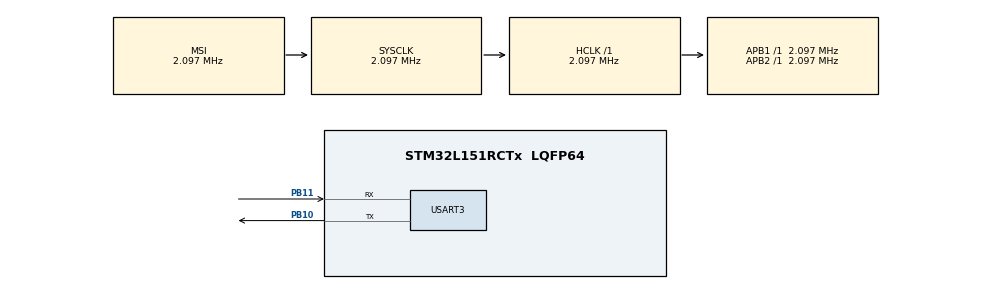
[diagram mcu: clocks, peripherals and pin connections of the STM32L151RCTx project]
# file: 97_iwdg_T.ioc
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IWDG.Prescaler=IWDG_PRESCALER_64
IWDG.Reload=500
Mcu.Family=STM32L1
Mcu.Name=STM32L151RCTx
Mcu.Package=LQFP64
NVIC.PriorityGroup=NVIC_PRIORITYGROUP_4
PB10.Mode=Asynchronous
PB10.Signal=USART3_TX
PB11.Mode=Asynchronous
PB11.Signal=USART3_RX
ProjectManager.HeapSize=0x200
ProjectManager.StackSize=0x400
ProjectManager.TargetToolchain=MDK-ARM V5.32
RCC.AHBFreq_Value=2097000
RCC.APB1Freq_Value=2097000
RCC.APB2Freq_Value=2097000
RCC.HSE_VALUE=24000000
RCC.HSI_VALUE=16000000
RCC.LSE_VALUE=32768
RCC.MSI_VALUE=2097000
RCC.SYSCLKFreq_VALUE=2097000
RCC.VCOOutputFreq_Value=48000000
USART3.VirtualMode=VM_ASYNC
VP_IWDG_VS_IWDG.Mode=IWDG_Activate
board=custom

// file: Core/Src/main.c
/* USER CODE BEGIN Header */
/**
  ******************************************************************************
  * @file           : main.c
  * @brief          : Main program body
  ******************************************************************************
  * @attention
  *
  * Copyright (c) 2024 STMicroelectronics.
  * All rights reserved.
  *
  * This software is licensed under terms that can be found in the LICENSE file
  * in the root directory of this software component.
  * If no LICENSE file comes with this software, it is provided AS-IS.
  *
  ******************************************************************************
  */
/* USER CODE END Header */
#include "main.h"

/* USER CODE BEGIN Includes */
#include "stdio.h"
/* USER CODE END Includes */

IWDG_HandleTypeDef hiwdg;

UART_HandleTypeDef huart3;

void SystemClock_Config(void);
static void MX_GPIO_Init(void);
static void MX_IWDG_Init(void);
static void MX_USART3_UART_Init(void);

int main(void)
{

  /* MCU Configuration--------------------------------------------------------*/

  /* Reset of all peripherals, Initializes the Flash interface and the Systick. */
  HAL_Init();

  /* Configure the system clock */
  SystemClock_Config();

  /* Initialize all configured peripherals */
  MX_GPIO_Init();
  MX_IWDG_Init();
  MX_USART3_UART_Init();
  /* USER CODE BEGIN 2 */
	char message[] = "message\r\n";
	sprintf(message, "reset\r\n");
	HAL_UART_Transmit(&huart3, (uint8_t *) message, sizeof(message) - 1, HAL_MAX_DELAY);
  /* USER CODE END 2 */

  /* Infinite loop */
  /* USER CODE BEGIN WHILE */
  while (1)
  {
  		HAL_Delay(100);
		sprintf(message, "feed\r\n");
		HAL_UART_Transmit(&huart3, (uint8_t *) message, sizeof(message) - 1, HAL_MAX_DELAY);
		// HAL_IWDG_Refresh(&hiwdg);  //ι��
    /* USER CODE END WHILE */

  }
}

void SystemClock_Config(void)
{
  RCC_OscInitTypeDef RCC_OscInitStruct = {0};
  RCC_ClkInitTypeDef RCC_ClkInitStruct = {0};

  /** Configure the main internal regulator output voltage
  */
  __HAL_PWR_VOLTAGESCALING_CONFIG(PWR_REGULATOR_VOLTAGE_SCALE1);

  /** Initializes the RCC Oscillators according to the specified parameters
  * in the RCC_OscInitTypeDef structure.
  */
  RCC_OscInitStruct.OscillatorType = RCC_OSCILLATORTYPE_LSI|RCC_OSCILLATORTYPE_MSI;
  RCC_OscInitStruct.LSIState = RCC_LSI_ON;
  RCC_OscInitStruct.MSIState = RCC_MSI_ON;
  RCC_OscInitStruct.MSICalibrationValue = 0;
  RCC_OscInitStruct.MSIClockRange = RCC_MSIRANGE_5;
  RCC_OscInitStruct.PLL.PLLState = RCC_PLL_NONE;
  if (HAL_RCC_OscConfig(&RCC_OscInitStruct) != HAL_OK)
  {
    Error_Handler();
  }

  /** Initializes the CPU, AHB and APB buses clocks
  */
  RCC_ClkInitStruct.ClockType = RCC_CLOCKTYPE_HCLK|RCC_CLOCKTYPE_SYSCLK
                              |RCC_CLOCKTYPE_PCLK1|RCC_CLOCKTYPE_PCLK2;
  RCC_ClkInitStruct.SYSCLKSource = RCC_SYSCLKSOURCE_MSI;
  RCC_ClkInitStruct.AHBCLKDivider = RCC_SYSCLK_DIV1;
  RCC_ClkInitStruct.APB1CLKDivider = RCC_HCLK_DIV1;
  RCC_ClkInitStruct.APB2CLKDivider = RCC_HCLK_DIV1;

  if (HAL_RCC_ClockConfig(&RCC_ClkInitStruct, FLASH_LATENCY_0) != HAL_OK)
  {
    Error_Handler();
  }
}

static void MX_IWDG_Init(void)
{

  hiwdg.Instance = IWDG;
  hiwdg.Init.Prescaler = IWDG_PRESCALER_64;
  hiwdg.Init.Reload = 500;
  if (HAL_IWDG_Init(&hiwdg) != HAL_OK)
  {
    Error_Handler();
  }

}

static void MX_USART3_UART_Init(void)
{

  huart3.Instance = USART3;
  huart3.Init.BaudRate = 115200;
  huart3.Init.WordLength = UART_WORDLENGTH_8B;
  huart3.Init.StopBits = UART_STOPBITS_1;
  huart3.Init.Parity = UART_PARITY_NONE;
  huart3.Init.Mode = UART_MODE_TX_RX;
  huart3.Init.HwFlowCtl = UART_HWCONTROL_NONE;
  huart3.Init.OverSampling = UART_OVERSAMPLING_16;
  if (HAL_UART_Init(&huart3) != HAL_OK)
  {
    Error_Handler();
  }

}

static void MX_GPIO_Init(void)
{

  /* GPIO Ports Clock Enable */
  __HAL_RCC_GPIOB_CLK_ENABLE();

}

void Error_Handler(void)
{
  __disable_irq();
  while (1)
  {
  }
}
